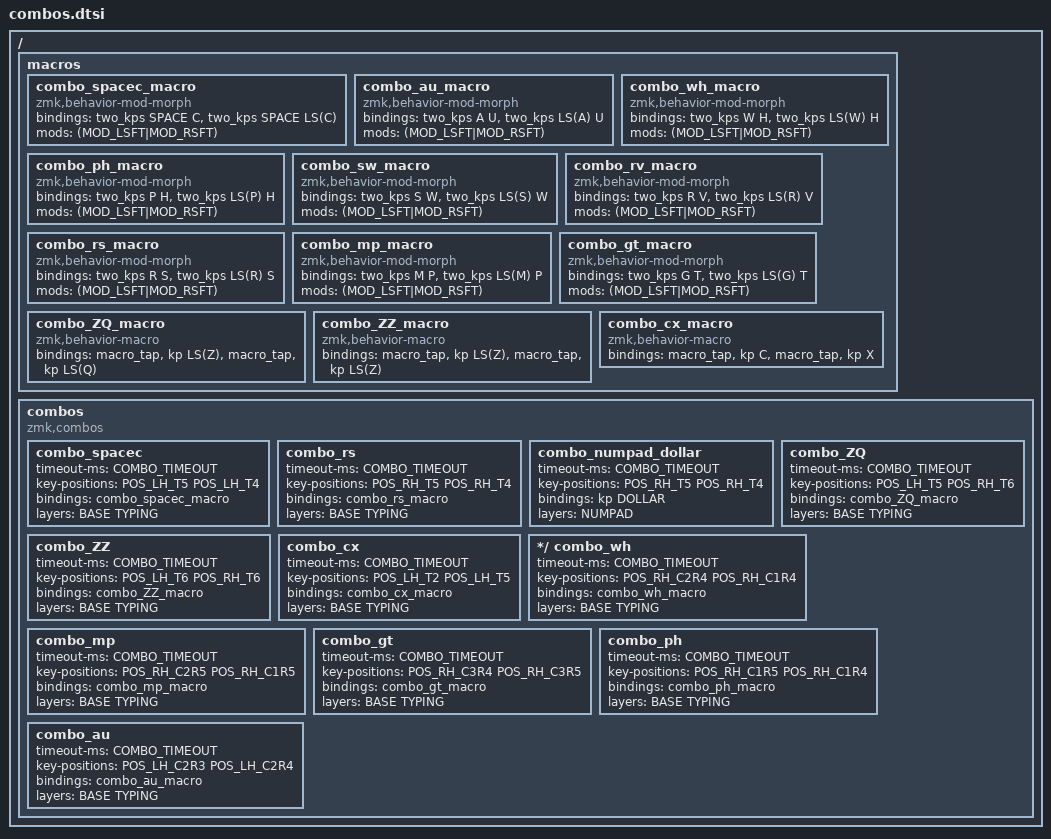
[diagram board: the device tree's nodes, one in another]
/ {
	macros {
		combo_spacec_macro: combo_spacec_macro {
			compatible = "zmk,behavior-mod-morph";
			#binding-cells = <0>;
			bindings = <&two_kps SPACE C>, <&two_kps SPACE LS(C)>;
			mods = <(MOD_LSFT|MOD_RSFT)>;
		};
		
		combo_au_macro: combo_au_macro {
			compatible = "zmk,behavior-mod-morph";
			#binding-cells = <0>;
			bindings = <&two_kps A U>, <&two_kps LS(A) U>;
			mods = <(MOD_LSFT|MOD_RSFT)>;
		};
		
		combo_wh_macro: combo_wh_macro {
			compatible = "zmk,behavior-mod-morph";
			#binding-cells = <0>;
			bindings = <&two_kps W H>, <&two_kps LS(W) H>;
			mods = <(MOD_LSFT|MOD_RSFT)>;
		};

		/* wh_and_kp: wh_and_kp { */
		/* 	compatible = "zmk,behavior-macro-one-param"; */
		/* 	#binding-cells = <1>; */
		/* 	bindings =  <&kp W>, */
		/* 	<&macro_param_1to2>, <&two_kps H MACRO_PLACEHOLDER>; */
		/* }; */
		/**/
		/* cwh_and_kp: cwh_and_kp { */
		/* 	compatible = "zmk,behavior-macro-one-param"; */
		/* 	#binding-cells = <1>; */
		/* 	bindings =  <&kp LS(W)>, */
		/* 	<&macro_param_1to2>, <&two_kps H MACRO_PLACEHOLDER>; */
		/* }; */
		/**/
		/* combo_wha_macro: combo_wha_macro { */
		/* 	compatible = "zmk,behavior-mod-morph"; */
		/* 	#binding-cells = <0>; */
		/* 	bindings = <&wh_and_kp A>, <&cwh_and_kp A>; */
		/* 	mods = <(MOD_LSFT|MOD_RSFT)>; */
		/* }; */
		
		combo_ph_macro: combo_ph_macro {
			compatible = "zmk,behavior-mod-morph";
			#binding-cells = <0>;
			bindings = <&two_kps P H>, <&two_kps LS(P) H>;
			mods = <(MOD_LSFT|MOD_RSFT)>;
		};
		
		combo_sw_macro: combo_sw_macro {
			compatible = "zmk,behavior-mod-morph";
			#binding-cells = <0>;
			bindings = <&two_kps S W>, <&two_kps LS(S) W>;
			mods = <(MOD_LSFT|MOD_RSFT)>;
		};
		
		combo_rv_macro: combo_rv_macro {
			compatible = "zmk,behavior-mod-morph";
			#binding-cells = <0>;
			bindings = <&two_kps R V>, <&two_kps LS(R) V>;
			mods = <(MOD_LSFT|MOD_RSFT)>;
		};
		
		combo_rs_macro: combo_rs_macro {
			compatible = "zmk,behavior-mod-morph";
			#binding-cells = <0>;
			bindings = <&two_kps R S>, <&two_kps LS(R) S>;
			mods = <(MOD_LSFT|MOD_RSFT)>;
		};
		
		combo_mp_macro: combo_mp_macro {
			compatible = "zmk,behavior-mod-morph";
			#binding-cells = <0>;
			bindings = <&two_kps M P>, <&two_kps LS(M) P>;
			mods = <(MOD_LSFT|MOD_RSFT)>;
		};
		
		combo_gt_macro: combo_gt_macro {
			compatible = "zmk,behavior-mod-morph";
			#binding-cells = <0>;
			bindings = <&two_kps G T>, <&two_kps LS(G) T>;
			mods = <(MOD_LSFT|MOD_RSFT)>;
		};
		
		combo_ZQ_macro: combo_ZQ_macro {
			compatible = "zmk,behavior-macro";
			#binding-cells = <0>;
			bindings = <&macro_tap &kp LS(Z)>, <&macro_tap &kp LS(Q)>;
		};
		
		combo_ZZ_macro: combo_ZZ_macro {
			compatible = "zmk,behavior-macro";
			#binding-cells = <0>;
			bindings = <&macro_tap &kp LS(Z)>, <&macro_tap &kp LS(Z)>;
		};
		
		combo_cx_macro: combo_cx_macro {
			compatible = "zmk,behavior-macro";
			#binding-cells = <0>;
			bindings = <&macro_tap &kp C>, <&macro_tap &kp X>;
		};
	};
};

/ {
	
	combos {
		compatible = "zmk,combos";
		
		#define COMBO_TIMEOUT 60
		
		/* combo_guiword { */
		/* 	timeout-ms = <COMBO_TIMEOUT>; */
		/* 	key-positions = <POS_LH_T4 POS_RH_T6>; */
		/* 	bindings = <&gui_word>; */
		/* 	layers = <BASE TYPING>; */
		/* }; */

		/* combo_second_numword { */
		/* 	timeout-ms = <COMBO_TIMEOUT>; */
		/* 	key-positions = <POS_LH_T4 POS_RH_T4 POS_LH_C2R4 POS_RH_C2R4>; */
		/* 	bindings = <&numword_with_overlay>; */
		/* 	layers = <BASE TYPING>; */
		/* }; */
		
		/* combo_numword { */
		/* 	timeout-ms = <COMBO_TIMEOUT>; */
		/* 	key-positions = <POS_LH_C2R5 POS_LH_C4R5>; */
		/* 	bindings = <&numword>; */
		/* 	layers = <BASE TYPING>; */
		/* }; */
		
		/* combo_mouseword { */
		/* 	timeout-ms = <COMBO_TIMEOUT>; */
		/* 	key-positions = <POS_LH_C3R5 POS_LH_T4>; */
		/* 	bindings = <&mouse_word>; */
		/* 	layers = <BASE TYPING>; */
		/* }; */
		
		combo_spacec {
			timeout-ms = <COMBO_TIMEOUT>;
			key-positions = <POS_LH_T5 POS_LH_T4>;
			bindings = <&combo_spacec_macro>;
			layers = <BASE TYPING>;
		};

		combo_rs {
			timeout-ms = <COMBO_TIMEOUT>;
			key-positions = <POS_RH_T5 POS_RH_T4>;
			bindings = <&combo_rs_macro>;
			layers = <BASE TYPING>;
		};

		combo_numpad_dollar {
			timeout-ms = <COMBO_TIMEOUT>;
			key-positions = <POS_RH_T5 POS_RH_T4>;
			bindings = <&kp DOLLAR>;
			layers = <NUMPAD>;
		};
		
		
		combo_ZQ {
			timeout-ms = <COMBO_TIMEOUT>;
			key-positions = <POS_LH_T5 POS_RH_T6>;
			bindings = <&combo_ZQ_macro>;
			layers = <BASE TYPING>;
		};
		
		combo_ZZ {
			timeout-ms = <COMBO_TIMEOUT>;
			key-positions = <POS_LH_T6 POS_RH_T6>;
			bindings = <&combo_ZZ_macro>;
			layers = <BASE TYPING>;
		};
		
		combo_cx {
			timeout-ms = <COMBO_TIMEOUT>;
			key-positions = <POS_LH_T2 POS_LH_T5>;
			bindings = <&combo_cx_macro>;
			layers = <BASE TYPING>;
		};
		
		/* combo_capsword { */
		/* 	timeout-ms = <COMBO_TIMEOUT>; */
		/* 	key-positions = <POS_LH_T1 POS_RH_T1>; */
		/* 	/* bindings = <&caps_word_with_layer>; */ */
		/* 	bindings = <&caps_word>; */
		/* 	layers = <BASE TYPING>; */
		/* }; */
		
		combo_wh {
			timeout-ms = <COMBO_TIMEOUT>;
			key-positions = <POS_RH_C2R4 POS_RH_C1R4>;
			bindings = <&combo_wh_macro>;
			layers = <BASE TYPING>;
		};
		
		/* combo_wha { */
		/* 	timeout-ms = <COMBO_TIMEOUT>; */
		/* 	key-positions = <POS_LH_C2R4 POS_RH_C2R4 POS_RH_C1R4>; */
		/* 	bindings = <&combo_wha_macro>; */
		/* 	layers = <BASE TYPING>; */
		/* }; */
		
		combo_mp {
			timeout-ms = <COMBO_TIMEOUT>;
			key-positions = <POS_RH_C2R5 POS_RH_C1R5>;
			bindings = <&combo_mp_macro>;
			layers = <BASE TYPING>;
		};
		
		combo_gt {
			timeout-ms = <COMBO_TIMEOUT>;
			key-positions = <POS_RH_C3R4 POS_RH_C3R5>;
			bindings = <&combo_gt_macro>;
			layers = <BASE TYPING>;
		};
		
		combo_ph {
			timeout-ms = <COMBO_TIMEOUT>;
			key-positions = <POS_RH_C1R5 POS_RH_C1R4>;
			bindings = <&combo_ph_macro>;
			layers = <BASE TYPING>;
		};
		
		combo_au {
			timeout-ms = <COMBO_TIMEOUT>;
			key-positions = <POS_LH_C2R3 POS_LH_C2R4>;
			bindings = <&combo_au_macro>;
			layers = <BASE TYPING>;
		};
	};
};
